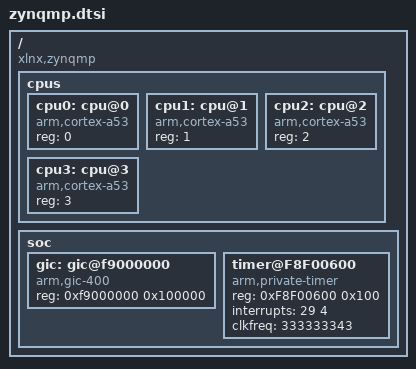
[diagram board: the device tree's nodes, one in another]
// SPDX-License-Identifier: MIT OR Apache-2.0
//
// Copyright (c) 2024 kwangdo.yi<kwangdo.yi@gmail.com>

/*
 * Included for example, not used
 */

/ {
	#address-cells = <1>;
	#size-cells = <1>;
	compatible = "xlnx,zynqmp";

	cpus {
		#address-cells = <1>;
		#size-cells = <0>;

		cpu0: cpu@0 {
			compatible = "arm,cortex-a53";
			device_type = "cpu";
			reg = <0>;
		};

		cpu1: cpu@1 {
			compatible = "arm,cortex-a53";
			device_type = "cpu";
			reg = <1>;
		};

		cpu2: cpu@2 {
			compatible = "arm,cortex-a53";
			device_type = "cpu";
			reg = <2>;
		};

		cpu3: cpu@3 {
			compatible = "arm,cortex-a53";
			device_type = "cpu";
			reg = <3>;
		};
	};

	soc {
		gic: gic@f9000000 {
			compatible = "arm,gic-400";
			reg = <0xf9000000 0x100000>;
		};
		timer@F8F00600 {
			compatible = "arm,private-timer";
			reg = <0xF8F00600 0x100>;
			interrupts = <29 4>;
			clkfreq = <333333343>;
		};
	};
};
